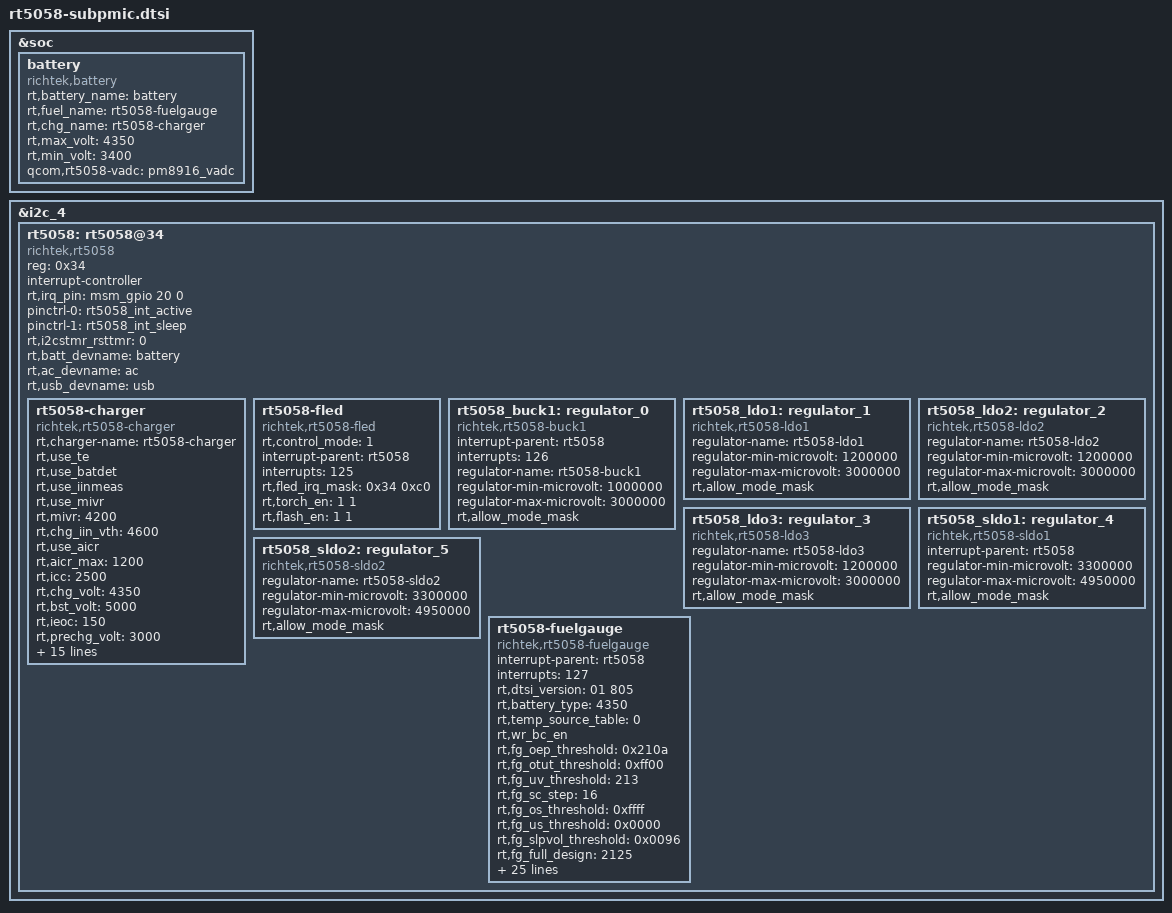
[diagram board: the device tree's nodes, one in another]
/* Copyright (c) 2015, The Linux Foundation. All rights reversed.
 *
 * This program is free software; you can redistribute it and/or modify
 * it under the terms of the GNU General Public License version 2 and
 * only version 2 as published by the Free Software Foundation.
 *
 * This program is distributed in the hope that it will be useful,
 * but WITHOUT ANY WARRANTY; without even the implied warranty of
 * MERCHANTABILITY or FITNESS FOR A PARTICULAR PURPOSE.  See the
 * GNU General Public License for more details.
 */

/* Please follow the proerty setting */
&soc {
	battery {
		compatible = "richtek,battery";
		rt,battery_name = "battery";
		rt,fuel_name = "rt5058-fuelgauge";
		rt,chg_name = "rt5058-charger";
		rt,max_volt = <4350>;
		rt,min_volt = <3400>;
		qcom,rt5058-vadc = <&pm8916_vadc>;
	};
};

&i2c_4 {

	rt5058: rt5058@34 {
		compatible = "richtek,rt5058";
		reg = <0x34>;
		interrupt-controller;
		#interrupt-cells = <1>;
		rt,irq_pin = <&msm_gpio 20 0>;
        pinctrl-names = "default", "sleep";
        pinctrl-0 = <&rt5058_int_active>;
        pinctrl-1 = <&rt5058_int_sleep>;
		rt,i2cstmr_rsttmr = <0>; /* 0: 0.5 sec, 1: 0.75 sec, 2: 1 sec, 3: 2 sec */
		rt,batt_devname = "battery";
		rt,ac_devname = "ac";
		rt,usb_devname = "usb";

		rt5058-charger {
			compatible = "richtek,rt5058-charger";
			rt,charger-name = "rt5058-charger";
			rt,use_te;
			rt,use_batdet;
			rt,use_iinmeas;
			rt,use_mivr;
			rt,mivr = <4200>;
			rt,chg_iin_vth = <4600>;
			rt,use_aicr;
			rt,aicr_max = <1200>;
			rt,icc = <2500>; /* charging current */
			rt,chg_volt = <4350>;
			rt,bst_volt = <5000>;
			rt,ieoc = <150>; /* 0: Disable, 1~19: 50mA~500mA */
			rt,prechg_volt = <3000>;
			rt,prechg_curr = <450>;
			rt,use_lbp; /* with it: enable low battery protection, without it:disable */
			rt,lbp_volt = <2800>;
			rt,backchg_time = <0>;
			rt,iinlmt_sel = <1>; /* 0:by chg_type, 1:by aicr,
						2:MAX(aicr, chg_type), 3:MIN(aicr, chg_type) */
			rt,sel_swfreq = <0>;
			rt,fixfreq = <0>;
			rt,fc_timer = <2>; /* 0~7: 4~16hr, 8:disable timer */
			rt,prc_timer = <0>; /* 0~2: 30,45,60 mins, 3:disable timer */
			rt,sys_minvolt = <1>; /* 0~3: 3.5V~3.8V */
			interrupt-parent = <&rt5058>;
			interrupts = <124>;
			interrupt-names = "CHG_IRQ";	// 124
			rt,chg_irq_mask = <0xf0 0x08 0xf0 0x1f 0xff>;
			rt,hocp = <0>; /* 0 is 2.5A, 1 is 3.5A */
			rt,temp_level = <(-40) 10 25 70>; // temperature levels for JEITA
			//rt,use_jeita;
		};
			rt5058-fled {
			compatible = "richtek,rt5058-fled";
			rt,control_mode = <1>; /* 0:i2c control, 1:pin control */
			interrupt-parent = <&rt5058>;
			interrupts = <125>;
			interrupt-names = "FLED_IRQ";
			rt,fled_irq_mask = <0x34 0xc0>;
			rt,torch_en = <1 1>;
			rt,flash_en = <1 1>;
		};
			rt5058_buck1: regulator_0 {
			compatible = "richtek,rt5058-buck1";
			interrupt-parent = <&rt5058>;
			interrupts = <126>;
			interrupt-names = "PMIC_IRQ";
			regulator-name = "rt5058-buck1";
			regulator-min-microvolt = <1000000>;
			regulator-max-microvolt = <3000000>;
			rt,allow_mode_mask;
		};

		rt5058_ldo1: regulator_1 {
			compatible = "richtek,rt5058-ldo1";
			regulator-name = "rt5058-ldo1";
			regulator-min-microvolt = <1200000>;
			regulator-max-microvolt = <3000000>;
			rt,allow_mode_mask;
		};

		rt5058_ldo2: regulator_2 {
			compatible = "richtek,rt5058-ldo2";
			regulator-name = "rt5058-ldo2";
			regulator-min-microvolt = <1200000>;
				regulator-max-microvolt = <3000000>;
				rt,allow_mode_mask;
		};

		rt5058_ldo3: regulator_3 {
			compatible = "richtek,rt5058-ldo3";
			regulator-name = "rt5058-ldo3";
			regulator-min-microvolt = <1200000>;
			regulator-max-microvolt = <3000000>;
			rt,allow_mode_mask;
		};

		rt5058_sldo1: regulator_4 {
			compatible = "richtek,rt5058-sldo1";
			interrupt-parent = <&rt5058>;
			regulator-min-microvolt = <3300000>;
			regulator-max-microvolt = <4950000>;
			rt,allow_mode_mask;
		};

		rt5058_sldo2: regulator_5 {
			compatible = "richtek,rt5058-sldo2";
			regulator-name = "rt5058-sldo2";
			regulator-min-microvolt = <3300000>;
			regulator-max-microvolt = <4950000>;
			rt,allow_mode_mask;
		};
		rt5058-fuelgauge {
			compatible = "richtek,rt5058-fuelgauge";
			interrupt-parent = <&rt5058>;
			interrupts = <127>;
			interrupt-names = "FUEL_IRQ";
			rt,dtsi_version = <01 805>;
			rt,battery_type = <4350>; // 4200 4350 4400
			rt,temp_source_table = <0>;
			rt,wr_bc_en; // with it -> enable wr_bc, without it -> disable wr_bc
			rt,fg_oep_threshold = <0x210a>; // battery over energy protection
			rt,fg_otut_threshold = <0xff00>; // over/under temperature
			rt,fg_uv_threshold = <213>; // under voltage 0~5100mV(unit: 20mV)
			rt,fg_sc_step = <16>; // soc chagne alert step (unit 0.0625%)
			rt,fg_os_threshold = <0xffff>; // over soc
			rt,fg_us_threshold = <0x0000>; // under soc
			rt,fg_slpvol_threshold = <0x0096>; // sleep voltage
			rt,fg_full_design = <2125>;
			rt,fg_op_config = <0x0220 0x0000 0x0000>;
			rt,fg_soc_config = <0x0110 0x0408>;
			rt,fg_irq_mask = <0xde7f 0xffff>;
			rt,fg_voltage_calibration = <0x0000>;
			rt,fg_current_calibration = <0x8080>;
			rt,cyc_adj_th = <100>;
			rt,cyc_adj_rat = <0>;
			rt,fg_aging_factor = <0x0032>;
			rt,fg_deadband = <0x0606>;
			rt,fg_comp_interpolation_order = <1 1 1>;
			rt,fg_comp_size = <1 3 1>;
			rt,offset_interpolation_order = <2 2>;
			rt,soc_offset_size = <6 1>;
			rt,soc_offset_data = <0    250 0
					15   250 0
					19   250 0
					20   250 0
					100  250 0
					1000 250 0>;
			rt,fg_function_table = <0 0x0 0x0 0x0 0x0 0x0 0x0 0x0 0x0
						0 0x0 0x0 0x0 0x0 0x0 0x0 0x0 0x0
						0 0x0 0x0 0x0 0x0 0x0 0x0 0x0 0x0
						0 0x0 0x0 0x0 0x0 0x0 0x0 0x0 0x0
						0 0x0 0x0 0x0 0x0 0x0 0x0 0x0 0x0>;
			rt,fg_soc_table = <0x0013 0x49c0 0x5500 0x588d 0x5b85 0x5c06 0x5c76 0x5e08
				0x5f43 0x6026 0x60e0 0x619d 0x6272 0x64d8 0x6688 0x6784
				0x6872 0x6975 0x6a8c 0x6ba6 0x2d00 0x038d 0x0249 0x0088
				0x001d 0x0054 0x0027 0x0036 0x0045 0x0066 0x0079 0x007a
				0x0069 0x0067 0x0071 0x0073 0x0051 0x0071 0x0013 0xff81
				0x0000 0x0200 0x049a 0x0680 0x0e4d 0x17e6 0x281a 0x309a
				0x3600 0x39b3 0x3d33 0x474d 0x4f80 0x5466 0x589a 0x5d1a
				0x6400 0x6900 0x0006 0x0048 0x0070 0x01e2 0x08ea 0x030f
				0x0699 0x04c6 0x03b9 0x0280 0x021c 0x021b 0x026e 0x027b
				0x0244 0x0239 0x032c 0x0243 0xb43c 0x0000 0x0000 0x0000>;
			rt,use_sc_count;
			/* BL46ZH_LGC_2125mAh_BATTERY */
			rt,lgc_battery_fg_comp_data = <3200 0    1000 43 20 15 110 128 7667 32100 0 1230
				3200 150  1000 30 55 65 125 128 4591 32100 0 1722
				3200 400  1000 55 60 120 120 128 3826 32100 0 1813>;
			/* BL49ZH_TOCAD_2125mAh_BATTERY */
			rt,tocad_battery_fg_comp_data = <3200 0    1000 45 25 25 80 128 7141 32100 0 1360
				3200 150  1000 30 55 75 125 128 4081 32100 0 1746
				3200 400  1000 60 65 130 130 128 3061 32100 0 1844>;
			qcom,rt5058-fg-vadc = <&pm8916_vadc>;
		};
	};
};
